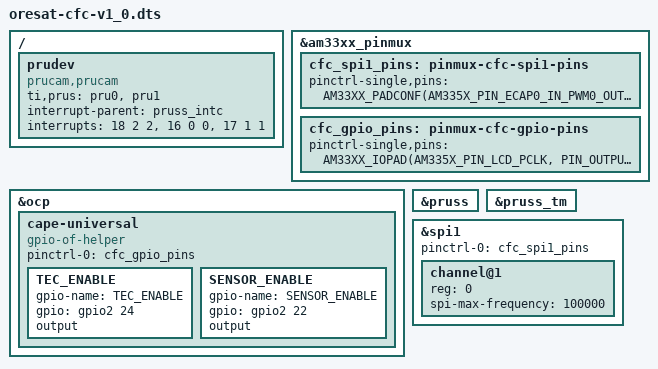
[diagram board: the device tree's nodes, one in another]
/* OreSat CFC v1.0 device tree */

/dts-v1/;

#include "oresat-base.dtsi"

/ {
  prudev {
    compatible = "prucam,prucam";

    ti,prus = <&pru0>, <&pru1>;
    interrupt-parent = <&pruss_intc>;

    interrupts = <18 2 2>, <16 0 0>, <17 1 1>;
    interrupt-names = "pru1_to_arm", "arm_to_prus", "pru0_to_pru1";
  };
};

&am33xx_pinmux {
  cfc_spi1_pins: pinmux-cfc-spi1-pins {
    pinctrl-single,pins = <
      AM33XX_PADCONF(AM335X_PIN_ECAP0_IN_PWM0_OUT, PIN_INPUT_PULLUP, MUX_MODE4) /* spi1_sclk */
      AM33XX_PADCONF(AM335X_PIN_UART0_CTSN, PIN_INPUT_PULLUP, MUX_MODE4) /* spi1_d0 */
      AM33XX_PADCONF(AM335X_PIN_UART0_RTSN, PIN_OUTPUT_PULLUP, MUX_MODE4) /* spi1_d1 */
      AM33XX_PADCONF(AM335X_PIN_SPI0_CS0, PIN_OUTPUT_PULLUP, MUX_MODE2) /* spi1_cs1 */
    >;
  };

  cfc_gpio_pins: pinmux-cfc-gpio-pins {
    pinctrl-single,pins = <
      AM33XX_IOPAD(AM335X_PIN_LCD_PCLK, PIN_OUTPUT | MUX_MODE7) /* gpio2_24 / TEC_ENABLE */
      AM33XX_IOPAD(AM335X_PIN_LCD_VSYNC, PIN_OUTPUT | MUX_MODE7) /* gpio2_22 / SENSOR_ENABLE */
      /* camera PRU pins */
      AM33XX_IOPAD(AM335X_PIN_MCASP0_ACLKX, PIN_INPUT | MUX_MODE6) /* pr1_pru0_pru_r31_0 */
      AM33XX_IOPAD(AM335X_PIN_MCASP0_FSX, PIN_INPUT | MUX_MODE6) /* pr1_pru0_pru_r31_1 */
      AM33XX_IOPAD(AM335X_PIN_MCASP0_AXR0, PIN_INPUT | MUX_MODE6) /* pr1_pru0_pru_r31_2 */
      AM33XX_IOPAD(AM335X_PIN_MCASP0_AHCLKR, PIN_INPUT | MUX_MODE6) /* pr1_pru0_pru_r31_3 */
      AM33XX_IOPAD(AM335X_PIN_MCASP0_ACLKR, PIN_INPUT | MUX_MODE6) /* pr1_pru0_pru_r31_4 */
      AM33XX_IOPAD(AM335X_PIN_MCASP0_FSR, PIN_INPUT | MUX_MODE6) /* pr1_pru0_pru_r31_5 */
      AM33XX_IOPAD(AM335X_PIN_MCASP0_AXR1, PIN_INPUT | MUX_MODE6) /* pr1_pru0_pru_r31_6 */
      AM33XX_IOPAD(AM335X_PIN_MCASP0_AHCLKX, PIN_INPUT | MUX_MODE6) /* pr1_pru0_pru_r31_7 */
      AM33XX_IOPAD(AM335X_PIN_GPMC_AD12, PIN_INPUT | MUX_MODE6) /* pr1_pru0_pru_r31_14 */
      AM33XX_IOPAD(AM335X_PIN_GPMC_AD13, PIN_INPUT | MUX_MODE6) /* pr1_pru0_pru_r31_15 */
      AM33XX_IOPAD(AM335X_PIN_XDMA_EVENT_INTR1, PIN_INPUT | MUX_MODE5) /* pr1_pru0_pru_r31_16 / MAX_CLKOUT */
    >;
  };
};

&ocp{ 
  cape-universal {
    compatible = "gpio-of-helper";
    status = "okay";
    pinctrl-names = "default";
    pinctrl-0 = <&cfc_gpio_pins>;

    TEC_ENABLE {
      gpio-name = "TEC_ENABLE";
      gpio = <&gpio2 24 GPIO_ACTIVE_HIGH>; /* AM335X_PIN_LCD_PCLK */
      output;
    };

    SENSOR_ENABLE {
      gpio-name = "SENSOR_ENABLE";
      gpio = <&gpio2 22 GPIO_ACTIVE_HIGH>; /* AM335X_PIN_LCD_VSYNC */
      output;
    };
  };
};

&pruss {
  status = "okay";
};

&pruss_tm {
  status = "okay";
};

&spi1 {
  #address-cells = <1>;
  #size-cells = <0>;
  status = "okay";
  pinctrl-names = "default";
  pinctrl-0 = <&cfc_spi1_pins>;

  channel@1 {
    #address-cells = <1>;
    #size-cells = <0>;
    reg = <0>;
    spi-max-frequency = <100000>;
    status = "okay";
  };
};
